# STM32WB55 register map
File version: 2.0
CPU: CM4 r0p1, little endian, MPU, FPU, 4 interrupt priority bits
Registers are 32-bit, read-write, reset 0x0 unless marked. A register's access mark holds for its fields unless they carry their own. Offsets are from the block's base; [hi:lo] are bit positions.

## IWDG — Independent watchdog
Base 0x40003000
0x00 KR wo — Key register
  [15:0] KEY — Key value (write only, read 0x0000)
0x04 PR — Prescaler register
  [2:0] PR — Prescaler divider
0x08 RLR reset 0xFFF — Reload register
  [11:0] RL — Watchdog counter reload value
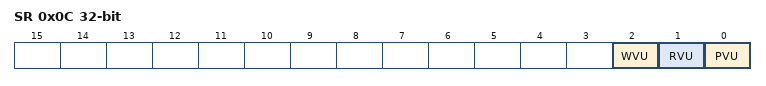
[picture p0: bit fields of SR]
0x0C SR ro — Status register
  [2] WVU — Watchdog counter window value update
  [1] RVU — Watchdog counter reload value update
  [0] PVU — Watchdog prescaler value update
0x10 WINR reset 0xFFF — Window register
  [11:0] WIN — Watchdog counter window value

## WWDG — System window watchdog
Base 0x40002C00
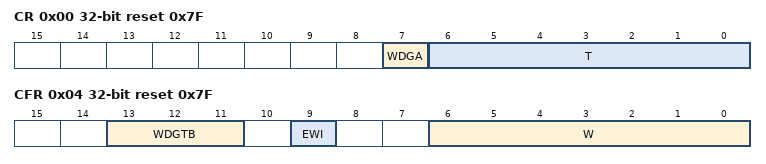
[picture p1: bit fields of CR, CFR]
0x00 CR reset 0x7F — Control register
  [7] WDGA — Activation bit
    0=Disabled (Watchdog disabled); 1=Enabled (Watchdog enabled)
  [6:0] T — 7-bit counter (MSB to LSB)
0x04 CFR reset 0x7F — Configuration register
  [13:11] WDGTB — Timer base
    0=Div1 (Counter clock (PCLK1 div 4096) div 1); 1=Div2 (Counter clock (PCLK1 div 4096) div 2); 2=Div4 (Counter clock (PCLK1 div 4096) div 4); 3=Div8 (Counter clock (PCLK1 div 4096) div 8); 4=Div16 (Counter clock (PCLK1 div 4096) div 16); 5=Div32 (Counter clock (PCLK1 div 4096) div 32); 6=Div64 (Counter clock (PCLK1 div 4096) div 64); 7=Div128 (Counter clock (PCLK1 div 4096) div 128)
  [9] EWI — Early wakeup interrupt
    on write: 1=Enable (interrupt occurs whenever the counter reaches the value 0x40)
  [6:0] W — 7-bit window value
0x08 SR — Status register
  [0] EWIF write-0-clears — Early wakeup interrupt flag
    on read: 0=Finished (The EWI Interrupt Service Routine has been serviced); 1=Pending (The EWI Interrupt Service Routine has been triggered) | on write: 0=Finished (The EWI Interrupt Service Routine has been serviced)

## COMP — Comparator instance 1
Base 0x40010200
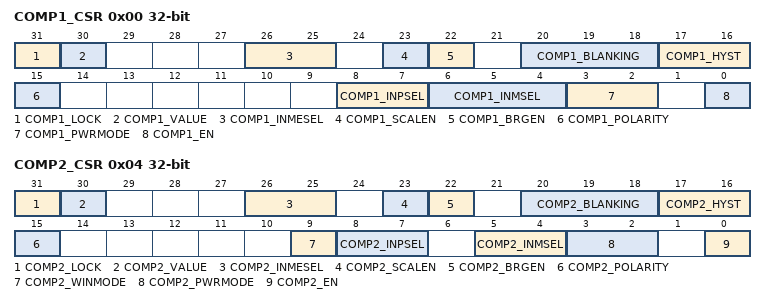
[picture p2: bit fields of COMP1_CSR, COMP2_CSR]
0x00 COMP1_CSR access per field — Comparator control and status register
  [31] COMP1_LOCK rw — Comparator lock
  [30] COMP1_VALUE ro — Comparator output level
  [26:25] COMP1_INMESEL rw — Comparator input minus extended selection
  [23] COMP1_SCALEN rw — Comparator scaler bridge enable
  [22] COMP1_BRGEN rw — Comparator voltage scaler enable
  [20:18] COMP1_BLANKING rw — Comparator blanking source
  [17:16] COMP1_HYST rw — Comparator hysteresis
  [15] COMP1_POLARITY rw — Comparator output polarity
  [8:7] COMP1_INPSEL rw — Comparator input plus selection
  [6:4] COMP1_INMSEL rw — Comparator input minus selection
  [3:2] COMP1_PWRMODE rw — Comparator power mode
  [0] COMP1_EN rw — Comparator enable
0x04 COMP2_CSR access per field — Comparator 2 control and status register
  [31] COMP2_LOCK rw — CSR register lock bit
  [30] COMP2_VALUE ro — Comparator 2 output status bit
  [26:25] COMP2_INMESEL rw — comparator 2 input minus extended selection bits.
  [23] COMP2_SCALEN rw — Voltage scaler enable bit
  [22] COMP2_BRGEN rw — Scaler bridge enable
  [20:18] COMP2_BLANKING rw — Comparator 2 blanking source selection bits
  [17:16] COMP2_HYST rw — Comparator 2 hysteresis selection bits
  [15] COMP2_POLARITY rw — Comparator 2 polarity selection bit
  [9] COMP2_WINMODE rw — Windows mode selection bit
  [8:7] COMP2_INPSEL rw — Comparator 1 input plus selection bit
  [5:4] COMP2_INMSEL rw — Comparator 2 input minus selection bits
  [3:2] COMP2_PWRMODE rw — Power Mode of the comparator 2
  [0] COMP2_EN rw — Comparator 2 enable bit

## RNG — Random number generator
Base 0x58001000
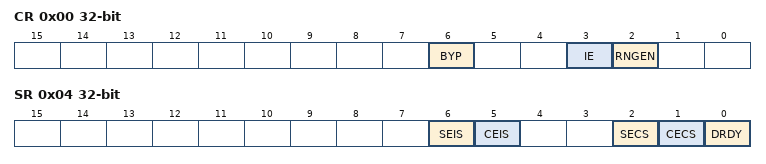
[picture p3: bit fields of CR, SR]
0x00 CR — control register
  [6] BYP — Bypass mode enable
  [3] IE — Interrupt enable
    0=Disabled (RNG interrupt is disabled); 1=Enabled (RNG interrupt is enabled)
  [2] RNGEN — Random number generator enable
    0=Disabled (Random number generator is disabled); 1=Enabled (Random number generator is enabled)
0x04 SR access per field — status register
  [6] SEIS rw write-0-clears — Seed error interrupt status
    on write: 0=Clear flag | on read: 0=No faulty sequence detected; 1=Fault (At least one faulty sequence has been detected. See **SECS** bit description for details. An interrupt is pending if IE = 1 in the RNG_CR register.)
  [5] CEIS rw write-0-clears — Clock error interrupt status
    on write: 0=Clear flag | on read: 0=Correct (The RNG clock is correct); 1=Slow (The RNG has been detected too slow An interrupt is pending if IE = 1 in the RNG_CR register)
  [2] SECS ro — Seed error current status
    0=No faulty sequence has currently been detected. If the SEIS bit is set, this means that a faulty sequence was detected and the situation has been recovered.; 1=Fault (At least one faulty sequence has been detected - see ref manual for details)
  [1] CECS ro — Clock error current status
    0=Correct (The RNG clock is correct. If the CEIS bit is set, this means that a slow clock was detected and the situation has been recovered.); 1=Slow (The RNG clock is too slow)
  [0] DRDY ro — Data ready
    0=Invalid (The RNG_DR register is not yet valid, no random data is available); 1=Valid (The RNG_DR register contains valid random data. Once the RNG_DR register has been read, this bit returns to 0 until a new random value is generated.)
0x08 DR ro — data register
  [31:0] RNDATA — Random data
